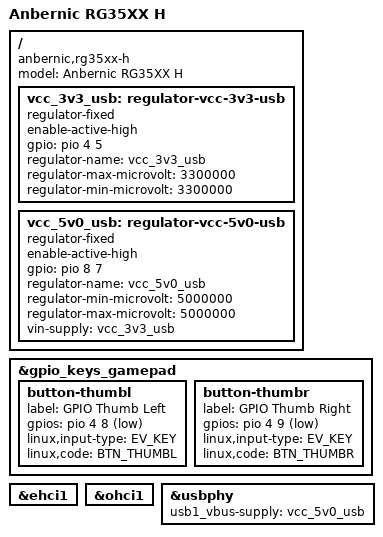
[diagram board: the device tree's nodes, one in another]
// SPDX-License-Identifier: (GPL-2.0-only OR BSD-2-Clause)
/*
 * Copyright (C) 2024 Ryan Walklin <ryan@testtoast.com>.
 * Copyright (C) 2024 Chris Morgan <macroalpha82@gmail.com>.
 */

#include "sun50i-h700-anbernic-rg35xx-plus.dts"

/ {
	model = "Anbernic RG35XX H";
	compatible = "anbernic,rg35xx-h", "allwinner,sun50i-h700";

	vcc_3v3_usb: regulator-vcc-3v3-usb {
		compatible = "regulator-fixed";
		enable-active-high;
		gpio = <&pio 4 5 GPIO_ACTIVE_HIGH>; /* PE5 */
		regulator-name = "vcc_3v3_usb";
		regulator-max-microvolt = <3300000>;
		regulator-min-microvolt = <3300000>;
	};

	vcc_5v0_usb: regulator-vcc-5v0-usb {
		compatible = "regulator-fixed";
		enable-active-high;
		gpio = <&pio 8 7 GPIO_ACTIVE_HIGH>; /* PI7 */
		regulator-name = "vcc_5v0_usb";
		regulator-min-microvolt = <5000000>;
		regulator-max-microvolt = <5000000>;
		vin-supply = <&vcc_3v3_usb>;
	};
};

&gpio_keys_gamepad {
	button-thumbl {
		label = "GPIO Thumb Left";
		gpios = <&pio 4 8 GPIO_ACTIVE_LOW>; /* PE8 */
		linux,input-type = <EV_KEY>;
		linux,code = <BTN_THUMBL>;
	};

	button-thumbr {
		label = "GPIO Thumb Right";
		gpios = <&pio 4 9 GPIO_ACTIVE_LOW>; /* PE9 */
		linux,input-type = <EV_KEY>;
		linux,code = <BTN_THUMBR>;
	};
};

&ehci1 {
	status = "okay";
};

&ohci1 {
	status = "okay";
};

&usbphy {
	usb1_vbus-supply = <&vcc_5v0_usb>;
};
